VERSION "J35_6AT"

NS_ :

BS_:

BU_: PCM UNKNOWN

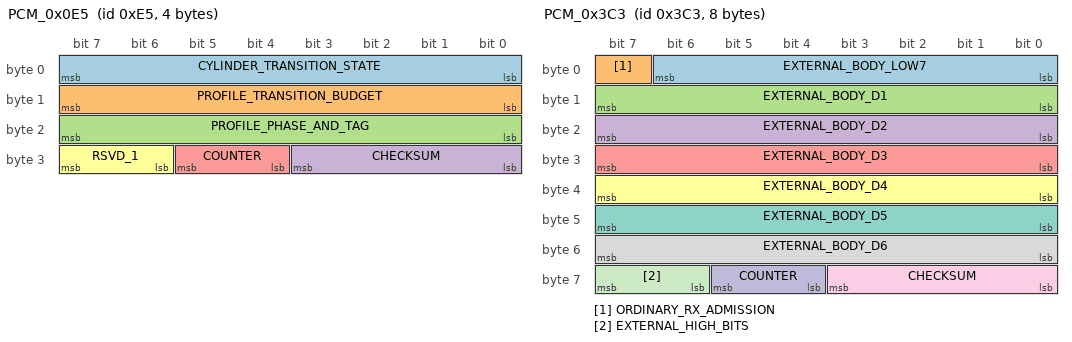
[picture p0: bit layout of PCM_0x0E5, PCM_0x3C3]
BO_ 229 PCM_0x0E5: 4 PCM
 SG_ CYLINDER_TRANSITION_STATE : 0|8@1+ (1,0) [0|255] ""  UNKNOWN
 SG_ PROFILE_TRANSITION_BUDGET : 8|8@1+ (1,0) [0|255] ""  UNKNOWN
 SG_ PROFILE_PHASE_AND_TAG : 16|8@1+ (1,0) [0|255] ""  UNKNOWN
 SG_ CHECKSUM : 24|4@1+ (1,0) [0|15] ""  UNKNOWN
 SG_ COUNTER : 28|2@1+ (1,0) [0|3] ""  UNKNOWN
 SG_ RSVD_1 : 30|2@1+ (1,0) [0|3] ""  UNKNOWN

BO_ 392 PCM_0x188: 6 PCM
 SG_ SHIFT_CONTROL_A : 0|4@1+ (1,0) [0|15] ""  UNKNOWN
 SG_ TRANSMISSION_LATCH : 4|1@1+ (1,0) [0|1] ""  UNKNOWN
 SG_ CONDITIONED_GEAR : 5|3@1+ (1,0) [0|7] ""  UNKNOWN
 SG_ SHIFT_CONTROL_B : 8|3@1+ (1,0) [0|7] ""  UNKNOWN
 SG_ LED_C : 11|1@1+ (1,0) [0|1] ""  UNKNOWN
 SG_ LED_B : 12|1@1+ (1,0) [0|1] ""  UNKNOWN
 SG_ LED_A : 13|1@1+ (1,0) [0|1] ""  UNKNOWN
 SG_ SIGNED_SPILL_D1 : 14|2@1+ (1,0) [0|3] ""  UNKNOWN
 SG_ SELECTOR_INDICATOR : 16|1@1+ (1,0) [0|1] ""  UNKNOWN
 SG_ TRANSMISSION_STATE : 17|1@1+ (1,0) [0|1] ""  UNKNOWN
 SG_ TRANSMISSION_QUALIFICATION : 18|1@1+ (1,0) [0|1] ""  UNKNOWN
 SG_ MANUAL_MODE_INDICATOR : 19|1@1+ (1,0) [0|1] ""  UNKNOWN
 SG_ INDICATOR_FAULT : 20|1@1+ (1,0) [0|1] ""  UNKNOWN
 SG_ TRANSMISSION_DIAGNOSTIC_LATCH : 21|1@1+ (1,0) [0|1] ""  UNKNOWN
 SG_ COMMUNICATION_STATUS : 22|1@1+ (1,0) [0|1] ""  UNKNOWN
 SG_ SHIFT_INDICATOR_CONTROL : 23|1@1+ (1,0) [0|1] ""  UNKNOWN
 SG_ AT_P_SWITCH : 24|1@1+ (1,0) [0|1] ""  UNKNOWN
 SG_ AT_R_SWITCH : 25|1@1+ (1,0) [0|1] ""  UNKNOWN
 SG_ AT_N_SWITCH : 26|1@1+ (1,0) [0|1] ""  UNKNOWN
 SG_ AT_D_SWITCH : 27|1@1+ (1,0) [0|1] ""  UNKNOWN
 SG_ RSVD_1 : 28|1@1+ (1,0) [0|1] ""  UNKNOWN
 SG_ AT_D3_SWITCH : 29|1@1+ (1,0) [0|1] ""  UNKNOWN
 SG_ AT_2_SWITCH_OR_AT_L_SWITCH : 30|1@1+ (1,0) [0|1] ""  UNKNOWN
 SG_ AT_1_SWITCH : 31|1@1+ (1,0) [0|1] ""  UNKNOWN
 SG_ SHIFT_POSITION_DISPLAY : 32|4@1+ (1,0) [0|15] ""  UNKNOWN
 SG_ AT_S_SWITCH : 36|1@1+ (1,0) [0|1] ""  UNKNOWN
 SG_ SERVICE_RESET_ACK : 37|1@1+ (1,0) [0|1] ""  UNKNOWN
 SG_ SERVICE_DUE : 38|1@1+ (1,0) [0|1] ""  UNKNOWN
 SG_ SIGNED_SPILL_D4 : 39|1@1+ (1,0) [0|1] ""  UNKNOWN
 SG_ CHECKSUM : 40|4@1+ (1,0) [0|15] ""  UNKNOWN
 SG_ COUNTER : 44|2@1+ (1,0) [0|3] ""  UNKNOWN
 SG_ QUALIFIED_TRANSMISSION_STATUS : 46|1@1+ (1,0) [0|1] ""  UNKNOWN
 SG_ RSVD_2 : 47|1@1+ (1,0) [0|1] ""  UNKNOWN
VAL_ 392 AT_S_SWITCH 0 "OFF" 1 "ON" ;
VAL_ 392 AT_1_SWITCH 0 "OFF" 1 "ON" ;
VAL_ 392 AT_D3_SWITCH 0 "OFF" 1 "ON" ;
VAL_ 392 AT_D_SWITCH 0 "OFF" 1 "ON" ;
VAL_ 392 AT_N_SWITCH 0 "OFF" 1 "ON" ;
VAL_ 392 AT_R_SWITCH 0 "OFF" 1 "ON" ;
VAL_ 392 AT_P_SWITCH 0 "OFF" 1 "ON" ;
VAL_ 392 MANUAL_MODE_INDICATOR 0 "OFF" 1 "ON" ;
VAL_ 392 LED_A 0 "OFF" 1 "ON" ;
VAL_ 392 LED_B 0 "OFF" 1 "ON" ;
VAL_ 392 LED_C 0 "OFF" 1 "ON" ;

BO_ 892 PCM_0x37C: 8 PCM
 SG_ UNKNOWN_1 : 0|8@1+ (1,0) [0|255] ""  UNKNOWN
 SG_ UNKNOWN_2 : 8|8@1+ (1,0) [0|255] ""  UNKNOWN
 SG_ UNKNOWN_3 : 16|8@1+ (1,0) [0|255] ""  UNKNOWN
 SG_ UNKNOWN_4 : 24|8@1+ (1,0) [0|255] ""  UNKNOWN
 SG_ RSVD_1 : 32|8@1+ (1,0) [0|255] ""  UNKNOWN
 SG_ UNKNOWN_5 : 40|7@1+ (1,0) [0|127] ""  UNKNOWN
 SG_ STATUS_BIT_1 : 47|1@1+ (1,0) [0|1] ""  UNKNOWN
 SG_ STATUS_BIT_2 : 48|1@1+ (1,0) [0|1] ""  UNKNOWN
 SG_ STATUS_BIT_3 : 49|1@1+ (1,0) [0|1] ""  UNKNOWN
 SG_ STATUS_BIT_4 : 50|1@1+ (1,0) [0|1] ""  UNKNOWN
 SG_ STATUS_BIT_5 : 51|1@1+ (1,0) [0|1] ""  UNKNOWN
 SG_ STATUS_BIT_6 : 52|1@1+ (1,0) [0|1] ""  UNKNOWN
 SG_ STATUS_BIT_7 : 53|1@1+ (1,0) [0|1] ""  UNKNOWN
 SG_ STATUS_BIT_8 : 54|1@1+ (1,0) [0|1] ""  UNKNOWN
 SG_ STATUS_BIT_9 : 55|1@1+ (1,0) [0|1] ""  UNKNOWN
 SG_ CHECKSUM : 56|4@1+ (1,0) [0|15] ""  UNKNOWN
 SG_ COUNTER : 60|2@1+ (1,0) [0|3] ""  UNKNOWN
 SG_ RSVD_2 : 62|1@1+ (1,0) [0|1] ""  UNKNOWN
 SG_ STATUS_BIT_10 : 63|1@1+ (1,0) [0|1] ""  UNKNOWN

BO_ 963 PCM_0x3C3: 8 PCM
 SG_ EXTERNAL_BODY_LOW7 : 0|7@1+ (1,0) [0|127] ""  UNKNOWN
 SG_ ORDINARY_RX_ADMISSION : 7|1@1+ (1,0) [0|1] ""  UNKNOWN
 SG_ EXTERNAL_BODY_D1 : 8|8@1+ (1,0) [0|255] ""  UNKNOWN
 SG_ EXTERNAL_BODY_D2 : 16|8@1+ (1,0) [0|255] ""  UNKNOWN
 SG_ EXTERNAL_BODY_D3 : 24|8@1+ (1,0) [0|255] ""  UNKNOWN
 SG_ EXTERNAL_BODY_D4 : 32|8@1+ (1,0) [0|255] ""  UNKNOWN
 SG_ EXTERNAL_BODY_D5 : 40|8@1+ (1,0) [0|255] ""  UNKNOWN
 SG_ EXTERNAL_BODY_D6 : 48|8@1+ (1,0) [0|255] ""  UNKNOWN
 SG_ CHECKSUM : 56|4@1+ (1,0) [0|15] ""  UNKNOWN
 SG_ COUNTER : 60|2@1+ (1,0) [0|3] ""  UNKNOWN
 SG_ EXTERNAL_HIGH_BITS : 62|2@1+ (1,0) [0|3] ""  UNKNOWN

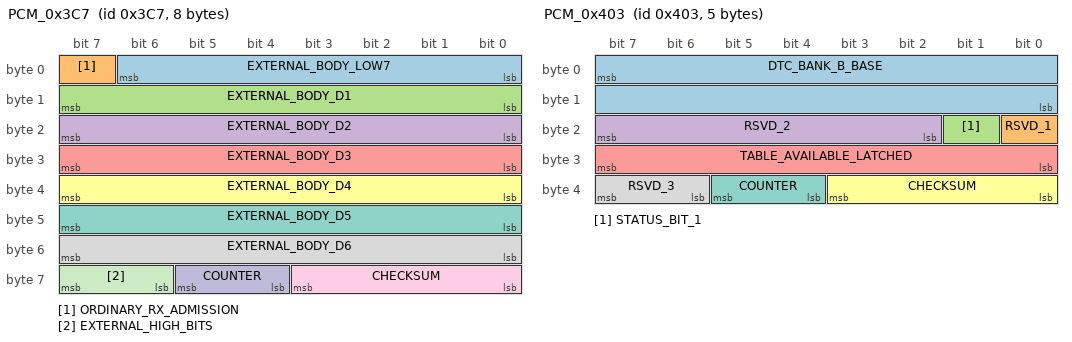
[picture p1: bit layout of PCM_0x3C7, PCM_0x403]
BO_ 967 PCM_0x3C7: 8 PCM
 SG_ EXTERNAL_BODY_LOW7 : 0|7@1+ (1,0) [0|127] ""  UNKNOWN
 SG_ ORDINARY_RX_ADMISSION : 7|1@1+ (1,0) [0|1] ""  UNKNOWN
 SG_ EXTERNAL_BODY_D1 : 8|8@1+ (1,0) [0|255] ""  UNKNOWN
 SG_ EXTERNAL_BODY_D2 : 16|8@1+ (1,0) [0|255] ""  UNKNOWN
 SG_ EXTERNAL_BODY_D3 : 24|8@1+ (1,0) [0|255] ""  UNKNOWN
 SG_ EXTERNAL_BODY_D4 : 32|8@1+ (1,0) [0|255] ""  UNKNOWN
 SG_ EXTERNAL_BODY_D5 : 40|8@1+ (1,0) [0|255] ""  UNKNOWN
 SG_ EXTERNAL_BODY_D6 : 48|8@1+ (1,0) [0|255] ""  UNKNOWN
 SG_ CHECKSUM : 56|4@1+ (1,0) [0|15] ""  UNKNOWN
 SG_ COUNTER : 60|2@1+ (1,0) [0|3] ""  UNKNOWN
 SG_ EXTERNAL_HIGH_BITS : 62|2@1+ (1,0) [0|3] ""  UNKNOWN

BO_ 1027 PCM_0x403: 5 PCM
 SG_ DTC_BANK_B_BASE : 7|16@0+ (1,0) [0|65535] ""  UNKNOWN
 SG_ RSVD_1 : 16|1@1+ (1,0) [0|1] ""  UNKNOWN
 SG_ STATUS_BIT_1 : 17|1@1+ (1,0) [0|1] ""  UNKNOWN
 SG_ RSVD_2 : 18|6@1+ (1,0) [0|63] ""  UNKNOWN
 SG_ TABLE_AVAILABLE_LATCHED : 24|8@1+ (1,0) [0|255] ""  UNKNOWN
 SG_ CHECKSUM : 32|4@1+ (1,0) [0|15] ""  UNKNOWN
 SG_ COUNTER : 36|2@1+ (1,0) [0|3] ""  UNKNOWN
 SG_ RSVD_3 : 38|2@1+ (1,0) [0|3] ""  UNKNOWN

BO_ 1039 PCM_0x40F: 8 PCM
 SG_ MULTIPLEX_PAGE M : 0|4@1+ (1,0) [0|15] ""  UNKNOWN
 SG_ MULTIPLEX_GROUP : 4|2@1+ (1,0) [0|3] ""  UNKNOWN
 SG_ DIAGNOSTIC_EVENT_STATE : 6|2@1+ (1,0) [0|3] ""  UNKNOWN
 SG_ UNKNOWN_1 m0 : 8|8@1+ (1,0) [0|255] ""  UNKNOWN
 SG_ P01_CONFIG_BYTE_1 m1 : 8|8@1+ (1,0) [0|255] ""  UNKNOWN
 SG_ P02_ENGINE_SPEED m2 : 8|8@1+ (50,0) [0|12750] "rpm"  UNKNOWN
 SG_ P03_ENGINE_COOLANT_TEMPERATURE m3 : 8|8@1+ (1,-40) [-40|215] "degC"  UNKNOWN
 SG_ P04_BARO_SENSOR_V m4 : 8|8@1+ (0.0196,0) [0|4.998] "V"  UNKNOWN
 SG_ P05_INPUT_SHAFT_MAINSHAFT_SPEED_RPM m5 : 15|16@0+ (1,0) [0|65535] "rpm"  UNKNOWN
 SG_ P06_AT_C_P_C_SOL_VLV_A_ACTUAL m6 : 8|8@1+ (0.005,0) [0|1.2750000000000001] "A"  UNKNOWN
 SG_ P07_LINE_PRESSURE_SOL_VLV_A m7 : 8|1@1+ (1,0) [0|1] ""  UNKNOWN
 SG_ RSVD_1 m8 : 8|8@1+ (1,0) [0|255] ""  UNKNOWN
 SG_ P07_SHIFT_SOLENOID_VALVE_G m7 : 9|1@1+ (1,0) [0|1] ""  UNKNOWN
 SG_ P07_SHIFT_SOLENOID_VALVE_F m7 : 10|1@1+ (1,0) [0|1] ""  UNKNOWN
 SG_ P07_AT_SHIFT_SOL_VLV_E m7 : 11|1@1+ (1,0) [0|1] ""  UNKNOWN
 SG_ P07_AT_SHIFT_SOL_VLV_D m7 : 12|1@1+ (1,0) [0|1] ""  UNKNOWN
 SG_ P07_AT_SHIFT_SOL_VLV_C m7 : 13|1@1+ (1,0) [0|1] ""  UNKNOWN
 SG_ P07_AT_SHIFT_SOL_VLV_B m7 : 14|1@1+ (1,0) [0|1] ""  UNKNOWN
 SG_ P07_AT_SHIFT_SOL_VLV_A m7 : 15|1@1+ (1,0) [0|1] ""  UNKNOWN
 SG_ UNKNOWN_2 m0 : 23|16@0+ (1,0) [0|65535] ""  UNKNOWN
 SG_ P01_CONFIG_BYTE_2 m1 : 16|8@1+ (1,0) [0|255] ""  UNKNOWN
 SG_ P02_OUTPUT_SHAFT_COUNTERSHAFT_SPEED m2 : 16|8@1+ (1,0) [0|255] "km/h"  UNKNOWN
 SG_ P03_BATTERY_VOLTAGE m3 : 16|8@1+ (0.1,0) [0|25.5] "V"  UNKNOWN
 SG_ P04_ATMOSPHERIC_PRESSURE m4 : 16|8@1+ (1,0) [0|255] "kPa"  UNKNOWN
 SG_ P06_AT_C_P_C_SOL_VLV_B_COMMAND m6 : 16|8@1+ (0.005,0) [0|1.2750000000000001] "A"  UNKNOWN
 SG_ P07_ATF_TEMP_SENSOR_V m7 : 16|8@1+ (0.0196,0) [0|4.998] "V"  UNKNOWN
 SG_ RSVD_2 m8 : 16|8@1+ (1,0) [0|255] ""  UNKNOWN
 SG_ P01_CONFIG_BYTE_3 m1 : 24|8@1+ (1,0) [0|255] ""  UNKNOWN
 SG_ P02_INPUT_SHAFT_MAINSHAFT_SPEED m2 : 24|8@1+ (1,0) [0|255] "km/h"  UNKNOWN
 SG_ P03_SHIFT_CONTROL m3 : 24|8@1+ (1,0) [0|255] ""  UNKNOWN
 SG_ P04_ENGINE_SPEED m4 : 31|16@0+ (1,0) [0|65535] "rpm"  UNKNOWN
 SG_ P05_APP_SENSOR m5 : 24|8@1+ (0.5,0) [0|127.5] "%"  UNKNOWN
 SG_ P06_AT_C_P_C_SOL_VLV_B_ACTUAL m6 : 24|8@1+ (0.005,0) [0|1.2750000000000001] "A"  UNKNOWN
 SG_ P07_ATF_TEMPERATURE m7 : 24|8@1+ (1,-40) [-40|215] "degC"  UNKNOWN
 SG_ RSVD_3 m8 : 24|8@1+ (1,0) [0|255] ""  UNKNOWN
 SG_ UNKNOWN_3 m0 : 32|8@1+ (1,0) [0|255] ""  UNKNOWN
 SG_ P01_CONFIG_BYTE_4 m1 : 32|8@1+ (1,0) [0|255] ""  UNKNOWN
 SG_ P02_TP_SENSOR_1 m2 : 32|8@1+ (0.0196,0) [0|4.998] "V"  UNKNOWN
 SG_ UNKNOWN_4 m3 : 32|8@1+ (1,0) [0|255] ""  UNKNOWN
 SG_ P05_APP_SENSOR_A_V m5 : 32|8@1+ (0.0196,0) [0|4.998] "V"  UNKNOWN
 SG_ P06_AT_C_P_C_SOL_VLV_C_COMMAND m6 : 32|8@1+ (0.005,0) [0|1.2750000000000001] "A"  UNKNOWN
 SG_ P07_AT_C_P_C_SOL_VLV_D_ACTUAL m7 : 32|8@1+ (0.005,0) [0|1.2750000000000001] "A"  UNKNOWN
 SG_ RSVD_4 m8 : 32|8@1+ (1,0) [0|255] ""  UNKNOWN
 SG_ RSVD_5 m0 : 47|16@0+ (1,0) [0|65535] ""  UNKNOWN
 SG_ P01_CONFIG_BYTE_5 m1 : 40|8@1+ (1,0) [0|255] ""  UNKNOWN
 SG_ P02_RELATIVE_TP_SENSOR m2 : 40|8@1+ (0.3921,0) [0|99.9855] "%"  UNKNOWN
 SG_ P03_MAP_SENSOR_V m3 : 40|8@1+ (0.0196,0) [0|4.998] "V"  UNKNOWN
 SG_ P04_OUTPUT_SHAFT_COUNTERSHAFT_SPEED_RPM m4 : 47|16@0+ (1,0) [0|65535] "rpm"  UNKNOWN
 SG_ P05_APP_SENSOR_B_V m5 : 40|8@1+ (0.0196,0) [0|4.998] "V"  UNKNOWN
 SG_ P06_AT_C_P_C_SOL_VLV_C_ACTUAL m6 : 40|8@1+ (0.005,0) [0|1.2750000000000001] "A"  UNKNOWN
 SG_ P07_AT_C_P_C_SOL_VLV_D_COMMAND m7 : 40|8@1+ (0.005,0) [0|1.2750000000000001] "A"  UNKNOWN
 SG_ RSVD_6 m8 : 40|8@1+ (1,0) [0|255] ""  UNKNOWN
 SG_ RSVD_8 m1 : 48|8@1+ (1,0) [0|255] ""  UNKNOWN
 SG_ P02_ECT_SENSOR_V m2 : 48|8@1+ (0.0196,0) [0|4.998] "V"  UNKNOWN
 SG_ P03_MANIFOLD_ABSOLUTE_PRESSURE m3 : 48|8@1+ (1,0) [0|255] "kPa"  UNKNOWN
 SG_ P05_AT_C_P_C_SOL_VLV_A_COMMAND m5 : 48|8@1+ (0.005,0) [0|1.2750000000000001] "A"  UNKNOWN
 SG_ P06_VEHICLE_SPEED m6 : 48|8@1+ (1,0) [0|255] "km/h"  UNKNOWN
 SG_ P07_LINE_PRESSURE_PRESSURE_SWITCH m7 : 48|1@1+ (1,0) [0|1] ""  UNKNOWN
 SG_ RSVD_7 m8 : 48|8@1+ (1,0) [0|255] ""  UNKNOWN
 SG_ P07_TRANSMISSION_FLUID_PRESSURE_SWITCH_B m7 : 49|1@1+ (1,0) [0|1] ""  UNKNOWN
 SG_ P07_TRANSMISSION_FLUID_PRESSURE_SWITCH_A m7 : 50|1@1+ (1,0) [0|1] ""  UNKNOWN
 SG_ P07_6TH_PRESSURE_SWITCH m7 : 51|1@1+ (1,0) [0|1] ""  UNKNOWN
 SG_ P07_5TH_PRESSURE_SWITCH m7 : 52|1@1+ (1,0) [0|1] ""  UNKNOWN
 SG_ P07_4TH_PRESSURE_SWITCH m7 : 53|1@1+ (1,0) [0|1] ""  UNKNOWN
 SG_ P07_3RD_PRESSURE_SWITCH m7 : 54|1@1+ (1,0) [0|1] ""  UNKNOWN
 SG_ P07_2ND_PRESSURE_SWITCH m7 : 55|1@1+ (1,0) [0|1] ""  UNKNOWN
 SG_ CHECKSUM : 56|4@1+ (1,0) [0|15] ""  UNKNOWN
 SG_ COUNTER : 60|2@1+ (1,0) [0|3] ""  UNKNOWN
 SG_ RSVD_9 : 62|2@1+ (1,0) [0|3] ""  UNKNOWN
VAL_ 1039 P07_2ND_PRESSURE_SWITCH 0 "OFF" 1 "ON" ;
VAL_ 1039 P07_3RD_PRESSURE_SWITCH 0 "OFF" 1 "ON" ;
VAL_ 1039 P07_4TH_PRESSURE_SWITCH 0 "OFF" 1 "ON" ;
VAL_ 1039 P07_5TH_PRESSURE_SWITCH 0 "OFF" 1 "ON" ;
VAL_ 1039 P07_6TH_PRESSURE_SWITCH 0 "OFF" 1 "ON" ;
VAL_ 1039 P07_TRANSMISSION_FLUID_PRESSURE_SWITCH_A 0 "OFF" 1 "ON" ;
VAL_ 1039 P07_TRANSMISSION_FLUID_PRESSURE_SWITCH_B 0 "OFF" 1 "ON" ;
VAL_ 1039 P07_LINE_PRESSURE_PRESSURE_SWITCH 0 "OFF" 1 "ON" ;
VAL_ 1039 P07_AT_SHIFT_SOL_VLV_A 0 "OFF" 1 "ON" ;
VAL_ 1039 P07_AT_SHIFT_SOL_VLV_B 0 "OFF" 1 "ON" ;
VAL_ 1039 P07_AT_SHIFT_SOL_VLV_C 0 "OFF" 1 "ON" ;
VAL_ 1039 P07_AT_SHIFT_SOL_VLV_D 0 "OFF" 1 "ON" ;
VAL_ 1039 P07_AT_SHIFT_SOL_VLV_E 0 "OFF" 1 "ON" ;
VAL_ 1039 P07_SHIFT_SOLENOID_VALVE_F 0 "OFF" 1 "ON" ;
VAL_ 1039 P07_SHIFT_SOLENOID_VALVE_G 0 "OFF" 1 "ON" ;
VAL_ 1039 P07_LINE_PRESSURE_SOL_VLV_A 0 "OFF" 1 "ON" ;
SG_MUL_VAL_ 1039 UNKNOWN_1 MULTIPLEX_PAGE 0-0;
SG_MUL_VAL_ 1039 P01_CONFIG_BYTE_1 MULTIPLEX_PAGE 1-1;
SG_MUL_VAL_ 1039 P02_ENGINE_SPEED MULTIPLEX_PAGE 2-2;
SG_MUL_VAL_ 1039 P03_ENGINE_COOLANT_TEMPERATURE MULTIPLEX_PAGE 3-3;
SG_MUL_VAL_ 1039 P04_BARO_SENSOR_V MULTIPLEX_PAGE 4-4;
SG_MUL_VAL_ 1039 P05_INPUT_SHAFT_MAINSHAFT_SPEED_RPM MULTIPLEX_PAGE 5-5;
SG_MUL_VAL_ 1039 P06_AT_C_P_C_SOL_VLV_A_ACTUAL MULTIPLEX_PAGE 6-6;
SG_MUL_VAL_ 1039 P07_LINE_PRESSURE_SOL_VLV_A MULTIPLEX_PAGE 7-7;
SG_MUL_VAL_ 1039 RSVD_1 MULTIPLEX_PAGE 8-15;
SG_MUL_VAL_ 1039 P07_SHIFT_SOLENOID_VALVE_G MULTIPLEX_PAGE 7-7;
SG_MUL_VAL_ 1039 P07_SHIFT_SOLENOID_VALVE_F MULTIPLEX_PAGE 7-7;
SG_MUL_VAL_ 1039 P07_AT_SHIFT_SOL_VLV_E MULTIPLEX_PAGE 7-7;
SG_MUL_VAL_ 1039 P07_AT_SHIFT_SOL_VLV_D MULTIPLEX_PAGE 7-7;
SG_MUL_VAL_ 1039 P07_AT_SHIFT_SOL_VLV_C MULTIPLEX_PAGE 7-7;
SG_MUL_VAL_ 1039 P07_AT_SHIFT_SOL_VLV_B MULTIPLEX_PAGE 7-7;
SG_MUL_VAL_ 1039 P07_AT_SHIFT_SOL_VLV_A MULTIPLEX_PAGE 7-7;
SG_MUL_VAL_ 1039 UNKNOWN_2 MULTIPLEX_PAGE 0-0;
SG_MUL_VAL_ 1039 P01_CONFIG_BYTE_2 MULTIPLEX_PAGE 1-1;
SG_MUL_VAL_ 1039 P02_OUTPUT_SHAFT_COUNTERSHAFT_SPEED MULTIPLEX_PAGE 2-2;
SG_MUL_VAL_ 1039 P03_BATTERY_VOLTAGE MULTIPLEX_PAGE 3-3;
SG_MUL_VAL_ 1039 P04_ATMOSPHERIC_PRESSURE MULTIPLEX_PAGE 4-4;
SG_MUL_VAL_ 1039 P06_AT_C_P_C_SOL_VLV_B_COMMAND MULTIPLEX_PAGE 6-6;
SG_MUL_VAL_ 1039 P07_ATF_TEMP_SENSOR_V MULTIPLEX_PAGE 7-7;
SG_MUL_VAL_ 1039 RSVD_2 MULTIPLEX_PAGE 8-15;
SG_MUL_VAL_ 1039 P01_CONFIG_BYTE_3 MULTIPLEX_PAGE 1-1;
SG_MUL_VAL_ 1039 P02_INPUT_SHAFT_MAINSHAFT_SPEED MULTIPLEX_PAGE 2-2;
SG_MUL_VAL_ 1039 P03_SHIFT_CONTROL MULTIPLEX_PAGE 3-3;
SG_MUL_VAL_ 1039 P04_ENGINE_SPEED MULTIPLEX_PAGE 4-4;
SG_MUL_VAL_ 1039 P05_APP_SENSOR MULTIPLEX_PAGE 5-5;
SG_MUL_VAL_ 1039 P06_AT_C_P_C_SOL_VLV_B_ACTUAL MULTIPLEX_PAGE 6-6;
SG_MUL_VAL_ 1039 P07_ATF_TEMPERATURE MULTIPLEX_PAGE 7-7;
SG_MUL_VAL_ 1039 RSVD_3 MULTIPLEX_PAGE 8-15;
SG_MUL_VAL_ 1039 UNKNOWN_3 MULTIPLEX_PAGE 0-0;
SG_MUL_VAL_ 1039 P01_CONFIG_BYTE_4 MULTIPLEX_PAGE 1-1;
SG_MUL_VAL_ 1039 P02_TP_SENSOR_1 MULTIPLEX_PAGE 2-2;
SG_MUL_VAL_ 1039 UNKNOWN_4 MULTIPLEX_PAGE 3-3;
SG_MUL_VAL_ 1039 P05_APP_SENSOR_A_V MULTIPLEX_PAGE 5-5;
SG_MUL_VAL_ 1039 P06_AT_C_P_C_SOL_VLV_C_COMMAND MULTIPLEX_PAGE 6-6;
SG_MUL_VAL_ 1039 P07_AT_C_P_C_SOL_VLV_D_ACTUAL MULTIPLEX_PAGE 7-7;
SG_MUL_VAL_ 1039 RSVD_4 MULTIPLEX_PAGE 8-15;
SG_MUL_VAL_ 1039 RSVD_5 MULTIPLEX_PAGE 0-0;
SG_MUL_VAL_ 1039 P01_CONFIG_BYTE_5 MULTIPLEX_PAGE 1-1;
SG_MUL_VAL_ 1039 P02_RELATIVE_TP_SENSOR MULTIPLEX_PAGE 2-2;
SG_MUL_VAL_ 1039 P03_MAP_SENSOR_V MULTIPLEX_PAGE 3-3;
SG_MUL_VAL_ 1039 P04_OUTPUT_SHAFT_COUNTERSHAFT_SPEED_RPM MULTIPLEX_PAGE 4-4;
SG_MUL_VAL_ 1039 P05_APP_SENSOR_B_V MULTIPLEX_PAGE 5-5;
SG_MUL_VAL_ 1039 P06_AT_C_P_C_SOL_VLV_C_ACTUAL MULTIPLEX_PAGE 6-6;
SG_MUL_VAL_ 1039 P07_AT_C_P_C_SOL_VLV_D_COMMAND MULTIPLEX_PAGE 7-7;
SG_MUL_VAL_ 1039 RSVD_6 MULTIPLEX_PAGE 8-15;
SG_MUL_VAL_ 1039 RSVD_8 MULTIPLEX_PAGE 1-1;
SG_MUL_VAL_ 1039 P02_ECT_SENSOR_V MULTIPLEX_PAGE 2-2;
SG_MUL_VAL_ 1039 P03_MANIFOLD_ABSOLUTE_PRESSURE MULTIPLEX_PAGE 3-3;
SG_MUL_VAL_ 1039 P05_AT_C_P_C_SOL_VLV_A_COMMAND MULTIPLEX_PAGE 5-5;
SG_MUL_VAL_ 1039 P06_VEHICLE_SPEED MULTIPLEX_PAGE 6-6;
SG_MUL_VAL_ 1039 P07_LINE_PRESSURE_PRESSURE_SWITCH MULTIPLEX_PAGE 7-7;
SG_MUL_VAL_ 1039 RSVD_7 MULTIPLEX_PAGE 8-15;
SG_MUL_VAL_ 1039 P07_TRANSMISSION_FLUID_PRESSURE_SWITCH_B MULTIPLEX_PAGE 7-7;
SG_MUL_VAL_ 1039 P07_TRANSMISSION_FLUID_PRESSURE_SWITCH_A MULTIPLEX_PAGE 7-7;
SG_MUL_VAL_ 1039 P07_6TH_PRESSURE_SWITCH MULTIPLEX_PAGE 7-7;
SG_MUL_VAL_ 1039 P07_5TH_PRESSURE_SWITCH MULTIPLEX_PAGE 7-7;
SG_MUL_VAL_ 1039 P07_4TH_PRESSURE_SWITCH MULTIPLEX_PAGE 7-7;
SG_MUL_VAL_ 1039 P07_3RD_PRESSURE_SWITCH MULTIPLEX_PAGE 7-7;
SG_MUL_VAL_ 1039 P07_2ND_PRESSURE_SWITCH MULTIPLEX_PAGE 7-7;

CM_ SG_ 1039 P02_ENGINE_SPEED "CANEAT: Engine Speed";
CM_ SG_ 1039 P02_OUTPUT_SHAFT_COUNTERSHAFT_SPEED "CANEAT: Output Shaft (CounterShaft) Speed";
CM_ SG_ 1039 P02_INPUT_SHAFT_MAINSHAFT_SPEED "CANEAT: Input Shaft (Mainshaft) Speed";
CM_ SG_ 1039 P02_TP_SENSOR_1 "CANEAT: TP Sensor 1";
CM_ SG_ 1039 P02_RELATIVE_TP_SENSOR "CANEAT: Relative TP Sensor";
CM_ SG_ 1039 P02_ECT_SENSOR_V "CANEAT: ECT Sensor (V)";
CM_ SG_ 1039 P03_ENGINE_COOLANT_TEMPERATURE "CANEAT: Engine Coolant Temperature";
CM_ SG_ 1039 P03_BATTERY_VOLTAGE "CANEAT: Battery Voltage";
CM_ SG_ 1039 P03_SHIFT_CONTROL "CANEAT: Shift Control";
CM_ SG_ 1039 P03_MAP_SENSOR_V "CANEAT: MAP Sensor (V)";
CM_ SG_ 1039 P03_MANIFOLD_ABSOLUTE_PRESSURE "CANEAT: Manifold Absolute Pressure";
CM_ SG_ 1039 P04_BARO_SENSOR_V "CANEAT: BARO SENSOR (V)";
CM_ SG_ 1039 P04_ATMOSPHERIC_PRESSURE "CANEAT: Atmospheric Pressure";
CM_ SG_ 1039 P04_ENGINE_SPEED "CANEAT: Engine Speed";
CM_ SG_ 1039 P04_OUTPUT_SHAFT_COUNTERSHAFT_SPEED_RPM "CANEAT: Output Shaft (CounterShaft) Speed (rpm)";
CM_ SG_ 1039 P05_INPUT_SHAFT_MAINSHAFT_SPEED_RPM "CANEAT: Input Shaft (Mainshaft) Speed (rpm)";
CM_ SG_ 1039 P05_APP_SENSOR "CANEAT: APP Sensor (%)";
CM_ SG_ 1039 P05_APP_SENSOR_A_V "CANEAT: APP Sensor A (V)";
CM_ SG_ 1039 P05_APP_SENSOR_B_V "CANEAT: APP Sensor B (V)";
CM_ SG_ 1039 P05_AT_C_P_C_SOL_VLV_A_COMMAND "CANEAT: A/T C.P.C. Sol VLV. A Command";
CM_ SG_ 1039 P06_AT_C_P_C_SOL_VLV_A_ACTUAL "CANEAT: A/T C.P.C. Sol VLV. A Actual";
CM_ SG_ 1039 P06_AT_C_P_C_SOL_VLV_B_COMMAND "CANEAT: A/T C.P.C. Sol VLV. B Command";
CM_ SG_ 1039 P06_AT_C_P_C_SOL_VLV_B_ACTUAL "CANEAT: A/T C.P.C. Sol VLV. B Actual";
CM_ SG_ 1039 P06_AT_C_P_C_SOL_VLV_C_COMMAND "CANEAT: A/T C.P.C. Sol VLV. C Command";
CM_ SG_ 1039 P06_AT_C_P_C_SOL_VLV_C_ACTUAL "CANEAT: A/T C.P.C. Sol VLV. C Actual";
CM_ SG_ 1039 P06_VEHICLE_SPEED "CANEAT: Vehicle Speed";
CM_ SG_ 1039 P07_LINE_PRESSURE_SOL_VLV_A "CANEAT: Line Pressure Sol VLV. A";
CM_ SG_ 1039 P07_SHIFT_SOLENOID_VALVE_G "CANEAT: Shift Solenoid Valve G";
CM_ SG_ 1039 P07_SHIFT_SOLENOID_VALVE_F "CANEAT: Shift Solenoid Valve F";
CM_ SG_ 1039 P07_AT_SHIFT_SOL_VLV_E "CANEAT: A/T Shift Sol VLV. E";
CM_ SG_ 1039 P07_AT_SHIFT_SOL_VLV_D "CANEAT: A/T Shift Sol VLV. D";
CM_ SG_ 1039 P07_AT_SHIFT_SOL_VLV_C "CANEAT: A/T Shift Sol VLV. C";
CM_ SG_ 1039 P07_AT_SHIFT_SOL_VLV_B "CANEAT: A/T Shift Sol VLV. B";
CM_ SG_ 1039 P07_AT_SHIFT_SOL_VLV_A "CANEAT: A/T Shift Sol VLV. A";
CM_ SG_ 1039 P07_ATF_TEMP_SENSOR_V "CANEAT: ATF Temp Sensor (V)";
CM_ SG_ 1039 P07_ATF_TEMPERATURE "CANEAT: ATF Temperature";
CM_ SG_ 1039 P07_AT_C_P_C_SOL_VLV_D_ACTUAL "CANEAT: A/T C.P.C. Sol VLV. D Actual";
CM_ SG_ 1039 P07_AT_C_P_C_SOL_VLV_D_COMMAND "CANEAT: A/T C.P.C. Sol VLV. D Command";
CM_ SG_ 1039 P07_LINE_PRESSURE_PRESSURE_SWITCH "CANEAT: Line Pressure Pressure Switch";
CM_ SG_ 1039 P07_TRANSMISSION_FLUID_PRESSURE_SWITCH_B "CANEAT: Transmission Fluid Pressure Switch B";
CM_ SG_ 1039 P07_TRANSMISSION_FLUID_PRESSURE_SWITCH_A "CANEAT: Transmission Fluid Pressure Switch A";
CM_ SG_ 1039 P07_6TH_PRESSURE_SWITCH "CANEAT: 6th Pressure Switch";
CM_ SG_ 1039 P07_5TH_PRESSURE_SWITCH "CANEAT: 5th Pressure Switch";
CM_ SG_ 1039 P07_4TH_PRESSURE_SWITCH "CANEAT: 4th Pressure Switch";
CM_ SG_ 1039 P07_3RD_PRESSURE_SWITCH "CANEAT: 3rd Pressure Switch";
CM_ SG_ 1039 P07_2ND_PRESSURE_SWITCH "CANEAT: 2nd Pressure Switch";
